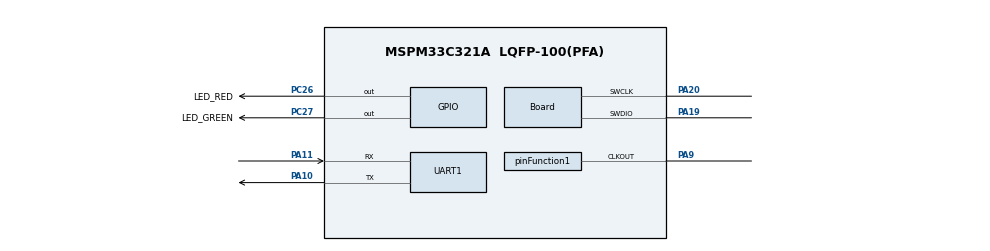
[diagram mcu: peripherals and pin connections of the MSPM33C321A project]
// uLisp on the LP-MSPM33C321A: TI's sysctl_mclk_syspll clock setup (SYSPLL, 160 MHz CPU), the two LEDs, and the back-channel UART (UC12, PA10 TX, PA11 RX) at 115200 with the receive interrupt.
//@cliArgs --device "MSPM33C321A" --package "LQFP-100(PFA)" --part "Default"
//@v2CliArgs --device "MSPM33C321A" --package "LQFP-100(PFA)"
// @cliArgs --board /ti/boards/LP_MSPM33C321A --rtos nortos

/**
 * Import the modules used in this configuration.
 */
const GPIO   = scripting.addModule("/ti/driverlib/GPIO", {}, false);
const GPIO1  = GPIO.addInstance();
const UART   = scripting.addModule("/ti/driverlib/UART", {}, false);
const UART1  = UART.addInstance();
const SYSCTL = scripting.addModule("/ti/driverlib/SYSCTL");

/**
 * Write custom configuration values to the imported modules.
 */
const divider1       = system.clockTree["EXCLKDIV"];
divider1.divideValue = 16;

const divider3       = system.clockTree["EXTDIVMCLK"];
divider3.divideValue = 1;

const gate4  = system.clockTree["EXCLKGATE"];
gate4.enable = true;

const multiplier2         = system.clockTree["PLL_QDIV"];
multiplier2.multiplyValue = 10;

const mux3       = system.clockTree["EXCLKMUX"];
mux3.inputSelect = "EXCLKMUX_ULPCLK";

const mux4       = system.clockTree["EXHFMUX"];
mux4.inputSelect = "EXHFMUX_XTAL";

const pinFunction1                        = system.clockTree["CLKOUT"];
pinFunction1.enable                       = true;
pinFunction1.peripheral.$assign           = "SYSCTL";
pinFunction1.peripheral.clkOutPin.$assign = "PA9";

GPIO1.$name                               = "GPIO_LEDS";
GPIO1.associatedPins.create(2);
GPIO1.associatedPins[0].$name             = "LED_GREEN";
GPIO1.associatedPins[0].launchPadShortcut = "LED2GreenEn";
GPIO1.associatedPins[0].pin.$assign       = "PC27";
GPIO1.associatedPins[1].$name             = "LED_RED";
GPIO1.associatedPins[1].launchPadShortcut = "LED2RedEn";
GPIO1.associatedPins[1].pin.$assign       = "PC26";

const Board                       = scripting.addModule("/ti/driverlib/Board", {}, false);
Board.peripheral.$assign          = "DEBUGSS";
Board.peripheral.swclkPin.$assign = "PA20";
Board.peripheral.swdioPin.$assign = "PA19";

SYSCTL.forceDefaultClkConfig = true;
SYSCTL.SYSPLL_Pdiv           = 1;
SYSCTL.MCLKSource            = "HSCLK";
SYSCTL.SYSPLL_CLK0En         = true;
SYSCTL.SYSPLL_CLK1En         = true;
SYSCTL.SYSPLL_CLK2XEn        = true;
SYSCTL.enableEXCLK           = true;
SYSCTL.EXCLKSource           = "ULPCLK";
SYSCTL.EXCLKDivider          = "16";
SYSCTL.clockTreeEn           = true;


UART1.$name                        = "UART_0";
UART1.targetBaudRate               = 115200;
UART1.enableFIFO                   = true;
UART1.enabledInterrupts            = ["RX","RX_TIMEOUT_ERROR"];
UART1.peripheral.$assign           = "UC12";
UART1.peripheral.rxPin.$assign     = "PA11";
UART1.peripheral.txPin.$assign     = "PA10";
UART1.txPinConfig.$name            = "ti_driverlib_gpio_GPIOPinGeneric0";
UART1.txPinConfig.enableConfig     = true;
UART1.rxPinConfig.$name            = "ti_driverlib_gpio_GPIOPinGeneric1";
UART1.rxPinConfig.enableConfig     = true;
UART1.rxPinConfig.internalResistor = "PULL_UP";

const ProjectConfig              = scripting.addModule("/ti/project_config/ProjectConfig", {}, false);
ProjectConfig.migrationCondition = true;
